# ATSAMA5D34 register map
Vendor: Microchip Technology; Series: SAMA5D3; File version: 0
Registers are 32-bit, read-write, reset 0x0 unless marked. A register's access mark holds for its fields unless they carry their own. Offsets are from the block's base; [hi:lo] are bit positions; {n}, {i} and the like mark numbered series.

## ADC — Analog-to-Digital Converter
Base 0xF8018000
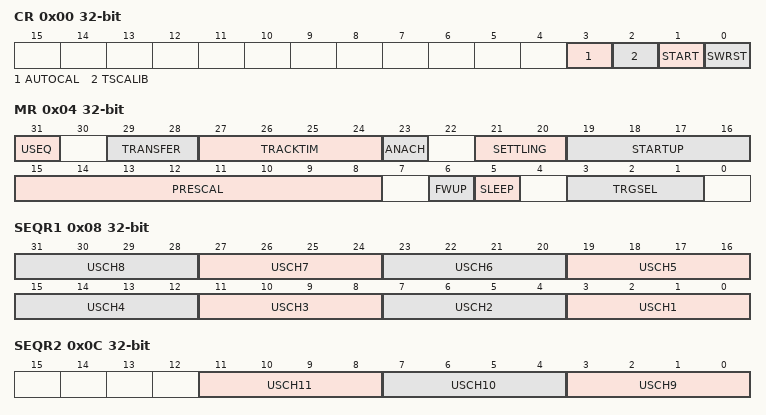
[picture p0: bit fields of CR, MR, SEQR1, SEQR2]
0x00 CR wo — Control Register
  [3] AUTOCAL — Automatic Calibration of ADC
  [2] TSCALIB — Touchscreen Calibration
  [1] START — Start Conversion
  [0] SWRST — Software Reset
0x04 MR — Mode Register
  [31] USEQ — Use Sequence Enable
    0=NUM_ORDER (Normal Mode: The controller converts channels in a simple numeric order depending only on the channel index.); 1=REG_ORDER (User Sequence Mode: The sequence respects what is defined in ADC_SEQR1 and ADC_SEQR2 registers and can be used to convert the same channel several times.)
  [29:28] TRANSFER — Transfer Time
  [27:24] TRACKTIM — Tracking Time
  [23] ANACH — Analog Change
    0=NONE (No analog change on channel switching: DIFF0, GAIN0 and OFF0 are used for all channels.); 1=ALLOWED (Allows different analog settings for each channel. See ADC_CGR and ADC_COR registers.)
  [21:20] SETTLING — Analog Settling Time
    0=AST3 (3 periods of ADCCLK); 1=AST5 (5 periods of ADCCLK); 2=AST9 (9 periods of ADCCLK); 3=AST17 (17 periods of ADCCLK)
  [19:16] STARTUP — Startup Time
    0=SUT0 (0 periods of ADCCLK); 1=SUT8 (8 periods of ADCCLK); 2=SUT16 (16 periods of ADCCLK); 3=SUT24 (24 periods of ADCCLK); 4=SUT64 (64 periods of ADCCLK); 5=SUT80 (80 periods of ADCCLK); 6=SUT96 (96 periods of ADCCLK); 7=SUT112 (112 periods of ADCCLK); 8=SUT512 (512 periods of ADCCLK); 9=SUT576 (576 periods of ADCCLK); 10=SUT640 (640 periods of ADCCLK); 11=SUT704 (704 periods of ADCCLK); 12=SUT768 (768 periods of ADCCLK); 13=SUT832 (832 periods of ADCCLK); 14=SUT896 (896 periods of ADCCLK); 15=SUT960 (960 periods of ADCCLK)
  [15:8] PRESCAL — Prescaler Rate Selection
  [6] FWUP — Fast Wake Up
    0=OFF (If SLEEP is 1, then both ADC core and reference voltage circuitry are OFF between conversions); 1=ON (If SLEEP is 1, then Fast Wake-up Sleep mode: The voltage reference is ON between conversions and ADC core is OFF)
  [5] SLEEP — Sleep Mode
    0=NORMAL (Normal Mode: The ADC core and reference voltage circuitry are kept ON between conversions.); 1=SLEEP (Sleep Mode: The wake-up time can be modified by programming FWUP bit.)
  [3:1] TRGSEL — Trigger Selection
    0=ADC_TRIG0 (ADTRG); 1=ADC_TRIG1 (TIOA0); 2=ADC_TRIG2 (TIOA1); 3=ADC_TRIG3 (TIOA2); 4=ADC_TRIG4 (PWM event line 0); 5=ADC_TRIG5 (PWM_even line 1)
0x08 SEQR1 — Channel Sequence Register 1
  [4n-1:4n-4] USCH{n} (n=1..8) — User Sequence Number {n}
0x0C SEQR2 — Channel Sequence Register 2
  [11:8] USCH11 — User Sequence Number 11
  [7:4] USCH10 — User Sequence Number 10
  [3:0] USCH9 — User Sequence Number 9
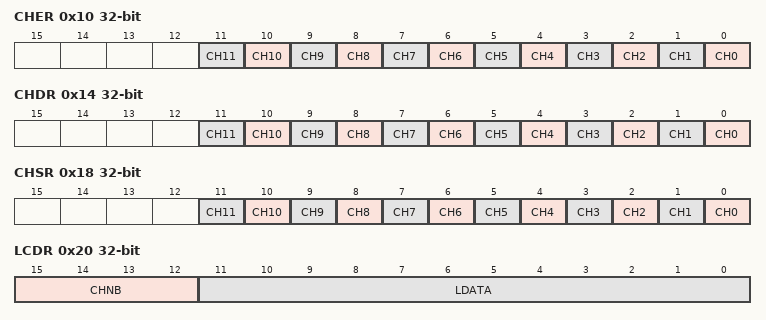
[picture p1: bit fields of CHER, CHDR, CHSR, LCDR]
0x10 CHER wo — Channel Enable Register
  [n] CH{n} (n=0..11) — Channel {n} Enable
0x14 CHDR wo — Channel Disable Register
  [n] CH{n} (n=0..11) — Channel {n} Disable
0x18 CHSR ro — Channel Status Register
  [n] CH{n} (n=0..11) — Channel {n} Status
0x20 LCDR ro — Last Converted Data Register
  [15:12] CHNB — Channel Number
  [11:0] LDATA — Last Data Converted
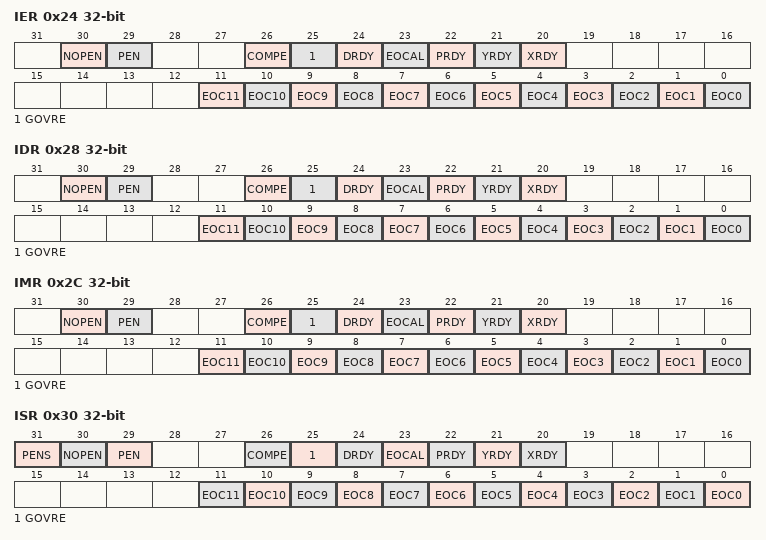
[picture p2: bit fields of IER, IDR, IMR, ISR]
0x24 IER wo — Interrupt Enable Register
  [30] NOPEN — No Pen Contact Interrupt Enable
  [29] PEN — Pen Contact Interrupt Enable
  [26] COMPE — Comparison Event Interrupt Enable
  [25] GOVRE — General Overrun Error Interrupt Enable
  [24] DRDY — Data Ready Interrupt Enable
  [23] EOCAL — End of Calibration Sequence
  [22] PRDY — Touchscreen Measure Pressure Ready Interrupt Enable
  [21] YRDY — Touchscreen Measure YPOS Ready Interrupt Enable
  [20] XRDY — Touchscreen Measure XPOS Ready Interrupt Enable
  [n] EOC{n} (n=0..11) — End of Conversion Interrupt Enable {n}
0x28 IDR wo — Interrupt Disable Register
  [30] NOPEN — No Pen Contact Interrupt Disable
  [29] PEN — Pen Contact Interrupt Disable
  [26] COMPE — Comparison Event Interrupt Disable
  [25] GOVRE — General Overrun Error Interrupt Disable
  [24] DRDY — Data Ready Interrupt Disable
  [23] EOCAL — End of Calibration Sequence
  [22] PRDY — Touchscreen Measure Pressure Ready Interrupt Disable
  [21] YRDY — Touchscreen Measure YPOS Ready Interrupt Disable
  [20] XRDY — Touchscreen Measure XPOS Ready Interrupt Disable
  [n] EOC{n} (n=0..11) — End of Conversion Interrupt Disable {n}
0x2C IMR ro — Interrupt Mask Register
  [30] NOPEN — No Pen Contact Interrupt Mask
  [29] PEN — Pen Contact Interrupt Mask
  [26] COMPE — Comparison Event Interrupt Mask
  [25] GOVRE — General Overrun Error Interrupt Mask
  [24] DRDY — Data Ready Interrupt Mask
  [23] EOCAL — End of Calibration Sequence
  [22] PRDY — Touchscreen Measure Pressure Ready Interrupt Mask
  [21] YRDY — Touchscreen Measure YPOS Ready Interrupt Mask
  [20] XRDY — Touchscreen Measure XPOS Ready Interrupt Mask
  [n] EOC{n} (n=0..11) — End of Conversion Interrupt Mask {n}
0x30 ISR ro — Interrupt Status Register
  [31] PENS — Pen Detect Status
  [30] NOPEN — No Pen Contact (cleared on read)
  [29] PEN — Pen contact (cleared on read)
  [26] COMPE — Comparison Event (cleared on read)
  [25] GOVRE — General Overrun Error (cleared on read)
  [24] DRDY — Data Ready (automatically set / cleared)
  [23] EOCAL — End of Calibration Sequence
  [22] PRDY — Touchscreen Pressure Measure Ready (cleared on read)
  [21] YRDY — Touchscreen YPOS Measure Ready (cleared on read)
  [20] XRDY — Touchscreen XPOS Measure Ready (cleared on read)
  [n] EOC{n} (n=0..11) — End of Conversion {n} (automatically set / cleared)
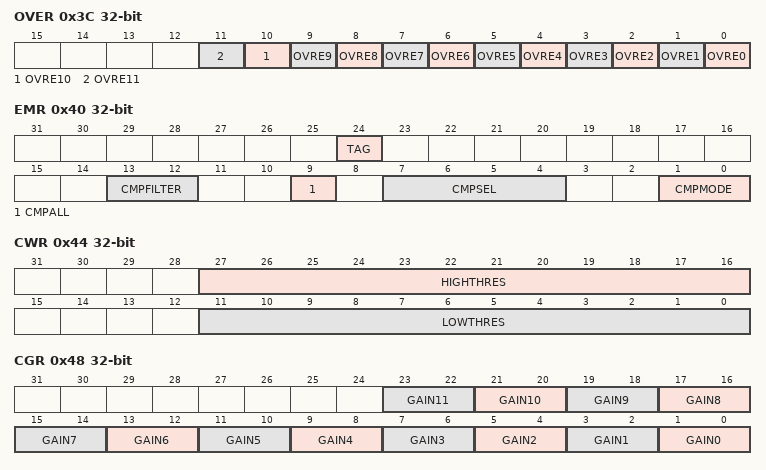
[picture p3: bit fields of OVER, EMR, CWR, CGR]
0x3C OVER ro — Overrun Status Register
  [n] OVRE{n} (n=0..11) — Overrun Error {n}
0x40 EMR — Extended Mode Register
  [24] TAG — Tag of ADC_LCDR
  [13:12] CMPFILTER — Compare Event Filtering
  [9] CMPALL — Compare All Channels
  [7:4] CMPSEL — Comparison Selected Channel
  [1:0] CMPMODE — Comparison Mode
    0=LOW (Generates an event when the converted data is lower than the low threshold of the window.); 1=HIGH (Generates an event when the converted data is higher than the high threshold of the window.); 2=IN (Generates an event when the converted data is in the comparison window.); 3=OUT (Generates an event when the converted data is out of the comparison window.)
0x44 CWR — Compare Window Register
  [27:16] HIGHTHRES — High Threshold
  [11:0] LOWTHRES — Low Threshold
0x48 CGR — Channel Gain Register
  [all] fields
    0=SE1_DIFF0_5 (Single-ended gain = 1 (ADC_COR.DIFFx = 0), differential gain = 0.5 (ADC_COR.DIFFx = 1)); 1=SE1_DIFF1 (Single-ended gain = 1 (ADC_COR.DIFFx = 0), differential gain = 1 (ADC_COR.DIFFx = 1)); 2=SE2_DIFF2 (Single-ended gain = 2 (ADC_COR.DIFFx = 0), differential gain = 2 (ADC_COR.DIFFx = 1)); 3=SE4_DIFF2 (Single-ended gain = 4 (ADC_COR.DIFFx = 0), differential gain = 2 (ADC_COR.DIFFx = 1))
  [2n+1:2n] GAIN{n} (n=0..11) — Gain for Channel {n}
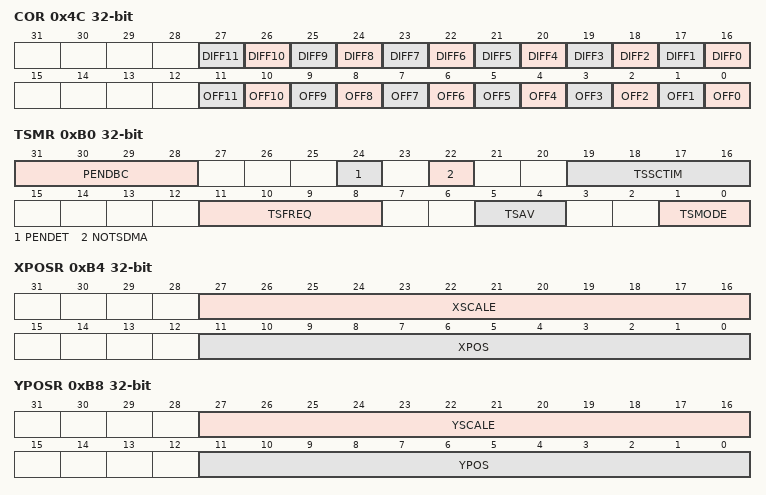
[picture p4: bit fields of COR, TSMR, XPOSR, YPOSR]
0x4C COR — Channel Offset Register
  [n+16] DIFF{n} (n=0..11) — Differential Inputs for Channel {n}
  [n] OFF{n} (n=0..11) — Offset for Channel {n}
{0x50+4i} CDR[{i}] (i=0..11) ro — Channel Data Register
  [11:0] DATA — Converted Data
0x94 ACR — Analog Control Register
  [1:0] PENDETSENS — Pen Detection Sensitivity
0xB0 TSMR — Touchscreen Mode Register
  [31:28] PENDBC — Pen Detect Debouncing Period
  [24] PENDET — Pen Contact Detection Enable
  [22] NOTSDMA — No TouchScreen DMA
  [19:16] TSSCTIM — Touchscreen Switches Closure Time
  [11:8] TSFREQ — Touchscreen Frequency
  [5:4] TSAV — Touchscreen Average
    0=NO_FILTER (No Filtering. Only one ADC conversion per measure); 1=AVG2CONV (Averages 2 ADC conversions); 2=AVG4CONV (Averages 4 ADC conversions); 3=AVG8CONV (Averages 8 ADC conversions)
  [1:0] TSMODE — Touchscreen Mode
    0=NONE (No Touchscreen); 1=_4_WIRE_NO_PM (4-wire Touchscreen without pressure measurement); 2=_4_WIRE (4-wire Touchscreen with pressure measurement); 3=_5_WIRE (5-wire Touchscreen)
0xB4 XPOSR ro — Touchscreen X Position Register
  [27:16] XSCALE — Scale of XPOS
  [11:0] XPOS — X Position
0xB8 YPOSR ro — Touchscreen Y Position Register
  [27:16] YSCALE — Scale of YPOS
  [11:0] YPOS — Y Position
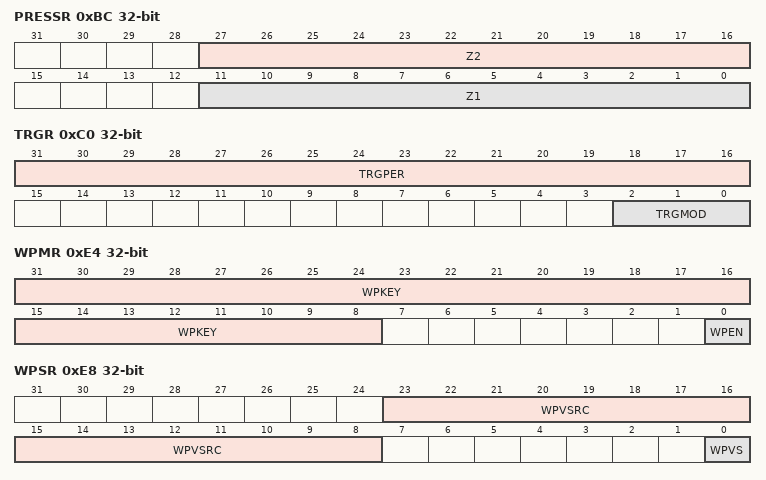
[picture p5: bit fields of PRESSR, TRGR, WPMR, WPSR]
0xBC PRESSR ro — Touchscreen Pressure Register
  [27:16] Z2 — Data of Z2 Measurement
  [11:0] Z1 — Data of Z1 Measurement
0xC0 TRGR — Trigger Register
  [31:16] TRGPER — Trigger Period
  [2:0] TRGMOD — Trigger Mode
    0=NO_TRIGGER (No trigger, only software trigger can start conversions); 1=EXT_TRIG_RISE (External trigger rising edge); 2=EXT_TRIG_FALL (External trigger falling edge); 3=EXT_TRIG_ANY (External trigger any edge); 4=PEN_TRIG (Pen Detect Trigger (shall be selected only if PENDET is set and TSAMOD = Touchscreen only mode)); 5=PERIOD_TRIG (ADC internal periodic trigger (see field TRGPER)); 6=CONTINUOUS (Continuous Mode)
0xE4 WPMR — Write Protection Mode Register
  [31:8] WPKEY — Write Protection Key
    0x414443=PASSWD (Writing any other value in this field aborts the write operation of the WPEN bit.Always reads as 0)
  [0] WPEN — Write Protection Enable
0xE8 WPSR ro — Write Protection Status Register
  [23:8] WPVSRC — Write Protection Violation Source
  [0] WPVS — Write Protection Violation Status

## Notices in the file
Copyright (c) 2026 Microchip Technology Inc.
SPDX-License-Identifier: Apache-2.0
Licensed under the Apache License, Version 2.0 (the "License");
you may not use this file except in compliance with the License.
You may obtain a copy of the License at
http://www.apache.org/licenses/LICENSE-2.0
Unless required by applicable law or agreed to in writing, software
distributed under the License is distributed on an "AS IS" BASIS,
WITHOUT WARRANTIES OR CONDITIONS OF ANY KIND, either express or implied.
See the License for the specific language governing permissions and
limitations under the License.
